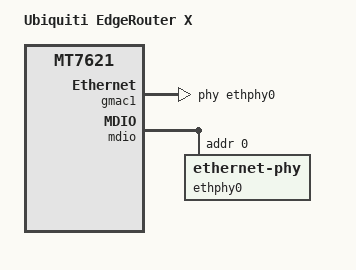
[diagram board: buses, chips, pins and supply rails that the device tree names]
#include "mt7621_ubnt_edgerouter-x.dtsi"

/ {
	model = "Ubiquiti EdgeRouter X";
	compatible = "ubnt,edgerouter-x", "mediatek,mt7621-soc";
};

&gmac1 {
	status = "okay";
	label = "eth0";
	phy-handle = <&ethphy0>;

	nvmem-cells = <&macaddr_factory_22>;
	nvmem-cell-names = "mac-address";
};

&mdio {
	ethphy0: ethernet-phy@0 {
		reg = <0>;
	};
};

&switch0 {
	ports {
		port@0 {
			status = "disabled";
		};
	};
};
